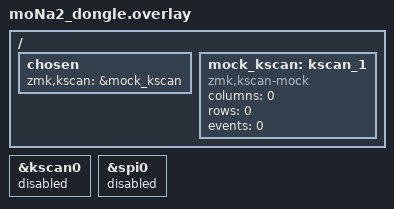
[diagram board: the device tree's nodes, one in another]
#include "moNa2.dtsi"

/ {
    chosen {
        zmk,kscan = &mock_kscan;
    };

    mock_kscan: kscan_1 {
        compatible = "zmk,kscan-mock";
        columns = <0>;
        rows = <0>;
        events = <0>;
    };
};

// Disable the original kscan0 which lacks col-gpios
&kscan0 {
    status = "disabled";
};

// Disable PMW3610 trackball sensor for dongle mode
&spi0 {
    status = "disabled";
};

// Remove trackball listener to prevent any PMW3610 references
/ {
    /delete-node/ trackball_listener;
};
